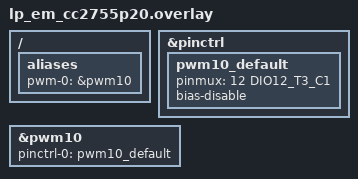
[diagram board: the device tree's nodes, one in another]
/*
 * Copyright (c) 2026 Texas Instruments Incorporated
 *
 * SPDX-License-Identifier: Apache-2.0
 */

#include <zephyr/dt-bindings/pinctrl/cc27xx-pinctrl.h>

/ {
	aliases {
		pwm-0 = &pwm10;
	};
};

&pinctrl {
	pwm10_default: pwm10_default {
		pinmux = <12 DIO12_T3_C1>;
		bias-disable;
	};
};

&pwm10 {
	status = "okay";
	pinctrl-0 = <&pwm10_default>;
	pinctrl-names = "default";
};
